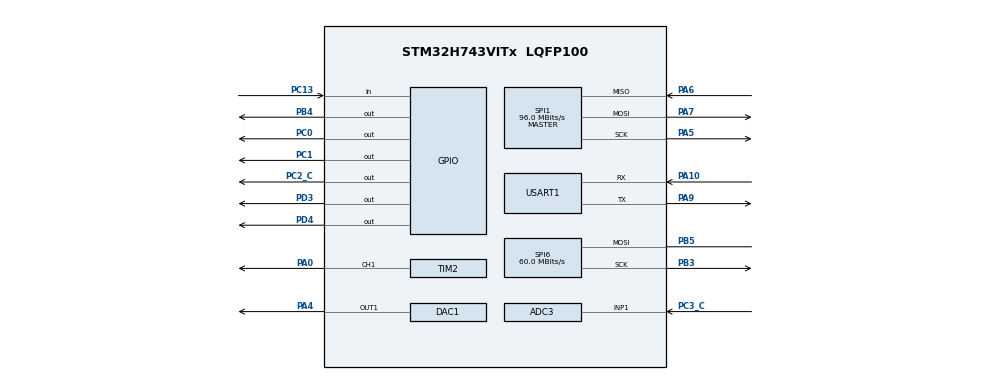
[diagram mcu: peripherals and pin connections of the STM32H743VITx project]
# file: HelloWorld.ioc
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ADC3.Channel-0\#ChannelRegularConversion=ADC_CHANNEL_1
ADC3.ClockPrescalerADC3=ADC_CLOCK_ASYNC_DIV2
ADC3.ContinuousConvMode=DISABLE
ADC3.ConversionDataManagement=ADC_CONVERSIONDATA_DMA_CIRCULAR
ADC3.DiscontinuousConvMode=DISABLE
ADC3.EnableAnalogWatchDog1=false
ADC3.ExternalTrigConv=ADC_EXTERNALTRIG_T1_CC1
ADC3.ExternalTrigConvEdge=ADC_EXTERNALTRIGCONVEDGE_RISING
ADC3.NbrOfConversion=1
ADC3.NbrOfConversionFlag=1
ADC3.OffsetNumber-0\#ChannelRegularConversion=ADC_OFFSET_NONE
ADC3.OffsetSignedSaturation-0\#ChannelRegularConversion=DISABLE
ADC3.Overrun=ADC_OVR_DATA_OVERWRITTEN
ADC3.Rank-0\#ChannelRegularConversion=1
ADC3.Resolution=ADC_RESOLUTION_12B
ADC3.SamplingTime-0\#ChannelRegularConversion=ADC_SAMPLETIME_1CYCLE_5
CORTEX_M7.AccessPermission_S-Cortex_Memory_Protection_Unit_Region1_Settings_S=MPU_REGION_FULL_ACCESS
CORTEX_M7.AccessPermission_S-Cortex_Memory_Protection_Unit_Region2_Settings_S=MPU_REGION_FULL_ACCESS
CORTEX_M7.AccessPermission_S-Cortex_Memory_Protection_Unit_Region3_Settings_S=MPU_REGION_FULL_ACCESS
CORTEX_M7.AccessPermission_S-Cortex_Memory_Protection_Unit_Region4_Settings_S=MPU_REGION_FULL_ACCESS
CORTEX_M7.AccessPermission_S-Cortex_Memory_Protection_Unit_Region5_Settings_S=MPU_REGION_FULL_ACCESS
CORTEX_M7.AccessPermission_Spec=MPU_REGION_FULL_ACCESS
CORTEX_M7.BaseAddress_S-Cortex_Memory_Protection_Unit_Region1_Settings_S=0x60000000
CORTEX_M7.BaseAddress_S-Cortex_Memory_Protection_Unit_Region2_Settings_S=0x30000000
CORTEX_M7.BaseAddress_S-Cortex_Memory_Protection_Unit_Region3_Settings_S=0x30020000
CORTEX_M7.BaseAddress_S-Cortex_Memory_Protection_Unit_Region4_Settings_S=0x30040000
CORTEX_M7.BaseAddress_S-Cortex_Memory_Protection_Unit_Region5_Settings_S=0x38000000
CORTEX_M7.BaseAddress_Spec=0x24000000
CORTEX_M7.CPU_DCache=Enabled
CORTEX_M7.CPU_ICache=Enabled
CORTEX_M7.DisableExec_Spec=MPU_INSTRUCTION_ACCESS_ENABLE
CORTEX_M7.Enable-Cortex_Memory_Protection_Unit_Region0_Settings=MPU_REGION_ENABLE
CORTEX_M7.Enable-Cortex_Memory_Protection_Unit_Region1_Settings=MPU_REGION_ENABLE
CORTEX_M7.Enable-Cortex_Memory_Protection_Unit_Region2_Settings=MPU_REGION_ENABLE
CORTEX_M7.Enable_S-Cortex_Memory_Protection_Unit_Region1_Settings_S=MPU_REGION_ENABLE
CORTEX_M7.Enable_S-Cortex_Memory_Protection_Unit_Region2_Settings_S=MPU_REGION_ENABLE
CORTEX_M7.Enable_S-Cortex_Memory_Protection_Unit_Region3_Settings_S=MPU_REGION_ENABLE
CORTEX_M7.Enable_S-Cortex_Memory_Protection_Unit_Region4_Settings_S=MPU_REGION_ENABLE
CORTEX_M7.Enable_S-Cortex_Memory_Protection_Unit_Region5_Settings_S=MPU_REGION_ENABLE
CORTEX_M7.IsBufferable_S-Cortex_Memory_Protection_Unit_Region1_Settings_S=MPU_ACCESS_BUFFERABLE
CORTEX_M7.IsBufferable_Spec=MPU_ACCESS_BUFFERABLE
CORTEX_M7.IsCacheable_S-Cortex_Memory_Protection_Unit_Region1_Settings_S=MPU_ACCESS_NOT_CACHEABLE
CORTEX_M7.IsCacheable_S-Cortex_Memory_Protection_Unit_Region2_Settings_S=MPU_ACCESS_CACHEABLE
CORTEX_M7.IsCacheable_S-Cortex_Memory_Protection_Unit_Region3_Settings_S=MPU_ACCESS_CACHEABLE
CORTEX_M7.IsCacheable_S-Cortex_Memory_Protection_Unit_Region4_Settings_S=MPU_ACCESS_CACHEABLE
CORTEX_M7.IsCacheable_S-Cortex_Memory_Protection_Unit_Region5_Settings_S=MPU_ACCESS_CACHEABLE
CORTEX_M7.IsCacheable_Spec=MPU_ACCESS_CACHEABLE
CORTEX_M7.IsShareable_S-Cortex_Memory_Protection_Unit_Region5_Settings_S=MPU_ACCESS_NOT_SHAREABLE
CORTEX_M7.IsShareable_Spec=MPU_ACCESS_NOT_SHAREABLE
CORTEX_M7.MPU_Control=MPU_HFNMI_PRIVDEF
CORTEX_M7.Size_S-Cortex_Memory_Protection_Unit_Region1_Settings_S=MPU_REGION_SIZE_64KB
CORTEX_M7.Size_S-Cortex_Memory_Protection_Unit_Region2_Settings_S=MPU_REGION_SIZE_128KB
CORTEX_M7.Size_S-Cortex_Memory_Protection_Unit_Region3_Settings_S=MPU_REGION_SIZE_128KB
CORTEX_M7.Size_S-Cortex_Memory_Protection_Unit_Region4_Settings_S=MPU_REGION_SIZE_32KB
CORTEX_M7.Size_S-Cortex_Memory_Protection_Unit_Region5_Settings_S=MPU_REGION_SIZE_64KB
CORTEX_M7.Size_Spec=MPU_REGION_SIZE_512KB
CORTEX_M7.SubRegionDisable_Spec=0x0
CORTEX_M7.TypeExtField_Spec=MPU_TEX_LEVEL1
CORTEX_M7.default_mode_Activation=1
DAC1.DAC1_OutputBuffer-DAC_OUT1=DAC_OUTPUTBUFFER_ENABLE
DAC1.DAC_Channel-DAC_OUT1=DAC_CHANNEL_1
DAC1.DAC_SampleAndHold-DAC_OUT1=DAC_SAMPLEANDHOLD_DISABLE
DAC1.DAC_Trigger-DAC_OUT1=DAC_TRIGGER_T6_TRGO
DAC1.DAC_UserTrimming-DAC_OUT1=DAC_TRIMMING_FACTORY
Dma.ADC3.2.Direction=DMA_PERIPH_TO_MEMORY
Dma.ADC3.2.EventEnable=DISABLE
Dma.ADC3.2.FIFOMode=DMA_FIFOMODE_ENABLE
Dma.ADC3.2.FIFOThreshold=DMA_FIFO_THRESHOLD_FULL
Dma.ADC3.2.Instance=DMA2_Stream0
Dma.ADC3.2.MemBurst=DMA_MBURST_SINGLE
Dma.ADC3.2.MemDataAlignment=DMA_MDATAALIGN_HALFWORD
Dma.ADC3.2.MemInc=DMA_MINC_ENABLE
Dma.ADC3.2.Mode=DMA_CIRCULAR
Dma.ADC3.2.PeriphBurst=DMA_PBURST_SINGLE
Dma.ADC3.2.PeriphDataAlignment=DMA_PDATAALIGN_HALFWORD
Dma.ADC3.2.PeriphInc=DMA_PINC_DISABLE
Dma.ADC3.2.Polarity=HAL_DMAMUX_REQ_GEN_RISING
Dma.ADC3.2.Priority=DMA_PRIORITY_HIGH
Dma.ADC3.2.RequestNumber=1
Dma.ADC3.2.SignalID=NONE
Dma.ADC3.2.SyncEnable=DISABLE
Dma.ADC3.2.SyncPolarity=HAL_DMAMUX_SYNC_NO_EVENT
Dma.ADC3.2.SyncRequestNumber=1
Dma.ADC3.2.SyncSignalID=NONE
Dma.DAC1_CH1.3.Direction=DMA_MEMORY_TO_PERIPH
Dma.DAC1_CH1.3.EventEnable=DISABLE
Dma.DAC1_CH1.3.FIFOMode=DMA_FIFOMODE_ENABLE
Dma.DAC1_CH1.3.FIFOThreshold=DMA_FIFO_THRESHOLD_FULL
Dma.DAC1_CH1.3.Instance=DMA2_Stream1
Dma.DAC1_CH1.3.MemBurst=DMA_MBURST_INC8
Dma.DAC1_CH1.3.MemDataAlignment=DMA_MDATAALIGN_HALFWORD
Dma.DAC1_CH1.3.MemInc=DMA_MINC_ENABLE
Dma.DAC1_CH1.3.Mode=DMA_CIRCULAR
Dma.DAC1_CH1.3.PeriphBurst=DMA_PBURST_SINGLE
Dma.DAC1_CH1.3.PeriphDataAlignment=DMA_PDATAALIGN_HALFWORD
Dma.DAC1_CH1.3.PeriphInc=DMA_PINC_DISABLE
Dma.DAC1_CH1.3.Polarity=HAL_DMAMUX_REQ_GEN_RISING
Dma.DAC1_CH1.3.Priority=DMA_PRIORITY_MEDIUM
Dma.DAC1_CH1.3.RequestNumber=1
Dma.DAC1_CH1.3.SignalID=NONE
Dma.DAC1_CH1.3.SyncEnable=DISABLE
Dma.DAC1_CH1.3.SyncPolarity=HAL_DMAMUX_SYNC_NO_EVENT
Dma.DAC1_CH1.3.SyncRequestNumber=1
Dma.DAC1_CH1.3.SyncSignalID=NONE
Dma.Request0=USART1_RX
Dma.Request1=USART1_TX
Dma.Request2=ADC3
Dma.Request3=DAC1_CH1
Dma.USART1_RX.0.Direction=DMA_PERIPH_TO_MEMORY
Dma.USART1_RX.0.EventEnable=DISABLE
Dma.USART1_RX.0.FIFOMode=DMA_FIFOMODE_DISABLE
Dma.USART1_RX.0.Instance=DMA1_Stream0
Dma.USART1_RX.0.MemDataAlignment=DMA_MDATAALIGN_BYTE
Dma.USART1_RX.0.MemInc=DMA_MINC_ENABLE
Dma.USART1_RX.0.Mode=DMA_CIRCULAR
Dma.USART1_RX.0.PeriphDataAlignment=DMA_PDATAALIGN_BYTE
Dma.USART1_RX.0.PeriphInc=DMA_PINC_DISABLE
Dma.USART1_RX.0.Polarity=HAL_DMAMUX_REQ_GEN_RISING
Dma.USART1_RX.0.Priority=DMA_PRIORITY_MEDIUM
Dma.USART1_RX.0.RequestNumber=1
Dma.USART1_RX.0.SignalID=NONE
Dma.USART1_RX.0.SyncEnable=DISABLE
Dma.USART1_RX.0.SyncPolarity=HAL_DMAMUX_SYNC_NO_EVENT
Dma.USART1_RX.0.SyncRequestNumber=1
Dma.USART1_RX.0.SyncSignalID=NONE
Dma.USART1_TX.1.Direction=DMA_MEMORY_TO_PERIPH
Dma.USART1_TX.1.EventEnable=DISABLE
Dma.USART1_TX.1.FIFOMode=DMA_FIFOMODE_ENABLE
Dma.USART1_TX.1.FIFOThreshold=DMA_FIFO_THRESHOLD_FULL
Dma.USART1_TX.1.Instance=DMA1_Stream1
Dma.USART1_TX.1.MemBurst=DMA_MBURST_INC16
Dma.USART1_TX.1.MemDataAlignment=DMA_MDATAALIGN_BYTE
Dma.USART1_TX.1.MemInc=DMA_MINC_ENABLE
Dma.USART1_TX.1.Mode=DMA_NORMAL
Dma.USART1_TX.1.PeriphBurst=DMA_PBURST_SINGLE
Dma.USART1_TX.1.PeriphDataAlignment=DMA_PDATAALIGN_BYTE
Dma.USART1_TX.1.PeriphInc=DMA_PINC_DISABLE
Dma.USART1_TX.1.Polarity=HAL_DMAMUX_REQ_GEN_RISING
Dma.USART1_TX.1.Priority=DMA_PRIORITY_MEDIUM
Dma.USART1_TX.1.RequestNumber=1
Dma.USART1_TX.1.SignalID=NONE
Dma.USART1_TX.1.SyncEnable=DISABLE
Dma.USART1_TX.1.SyncPolarity=HAL_DMAMUX_SYNC_NO_EVENT
Dma.USART1_TX.1.SyncRequestNumber=1
Dma.USART1_TX.1.SyncSignalID=NONE
Mcu.Family=STM32H7
Mcu.Name=STM32H743VITx
Mcu.Package=LQFP100
NVIC.DMA1_Stream0_IRQn=true\:0\:0\:false\:false\:true\:false\:true\:true
NVIC.DMA1_Stream1_IRQn=true\:0\:0\:false\:false\:true\:false\:true\:true
NVIC.DMA2_Stream0_IRQn=true\:0\:0\:false\:false\:true\:false\:true\:true
NVIC.DMA2_Stream1_IRQn=true\:0\:0\:false\:false\:true\:false\:true\:true
NVIC.PriorityGroup=NVIC_PRIORITYGROUP_4
NVIC.TIM7_IRQn=true\:0\:0\:false\:false\:true\:true\:true\:true
NVIC.USART1_IRQn=true\:0\:0\:false\:false\:true\:true\:true\:true
PA0.Signal=S_TIM2_CH1_ETR
PA10.Mode=Asynchronous
PA10.Signal=USART1_RX
PA13\ (JTMS/SWDIO).Mode=Serial_Wire
PA13\ (JTMS/SWDIO).Signal=DEBUG_JTMS-SWDIO
PA14\ (JTCK/SWCLK).Mode=Serial_Wire
PA14\ (JTCK/SWCLK).Signal=DEBUG_JTCK-SWCLK
PA4.Signal=COMP_DAC11_group
PA5.Mode=Full_Duplex_Master
PA5.Signal=SPI1_SCK
PA6.Mode=Full_Duplex_Master
PA6.Signal=SPI1_MISO
PA7.Mode=Full_Duplex_Master
PA7.Signal=SPI1_MOSI
PA9.Mode=Asynchronous
PA9.Signal=USART1_TX
PB3\ (JTDO/TRACESWO).GPIO_PuPd=GPIO_PULLUP
PB3\ (JTDO/TRACESWO).GPIO_Speed=GPIO_SPEED_FREQ_VERY_HIGH
PB3\ (JTDO/TRACESWO).Mode=Simplex_Bidirectional_Master
PB3\ (JTDO/TRACESWO).Signal=SPI6_SCK
PB4\ (NJTRST).Signal=GPIO_Output
PB5.GPIO_PuPd=GPIO_PULLUP
PB5.GPIO_Speed=GPIO_SPEED_FREQ_VERY_HIGH
PB5.Mode=Simplex_Bidirectional_Master
PB5.Signal=SPI6_MOSI
PC0.Signal=GPIO_Output
PC1.Signal=GPIO_Output
PC13.Signal=GPIO_Input
PC2_C.Signal=GPIO_Output
PC3_C.Mode=IN1-Single-Ended
PC3_C.Signal=ADC3_INP1
PD3.Signal=GPIO_Output
PD4.Signal=GPIO_Output
PH0-OSC_IN\ (PH0).Mode=HSE-External-Oscillator
PH0-OSC_IN\ (PH0).Signal=RCC_OSC_IN
PH1-OSC_OUT\ (PH1).Mode=HSE-External-Oscillator
PH1-OSC_OUT\ (PH1).Signal=RCC_OSC_OUT
ProjectManager.HeapSize=0x2000
ProjectManager.StackSize=0x1000
ProjectManager.TargetToolchain=STM32CubeIDE
RCC.ADCFreq_Value=75000000
RCC.APB1Freq_Value=120000000
RCC.APB2Freq_Value=120000000
RCC.APB3Freq_Value=120000000
RCC.APB4Freq_Value=120000000
RCC.CortexFreq_Value=480000000
RCC.D1PPRE=RCC_APB3_DIV2
RCC.D2PPRE1=RCC_APB1_DIV2
RCC.D2PPRE2=RCC_APB2_DIV2
RCC.D3PPRE=RCC_APB4_DIV2
RCC.DIVM1=5
RCC.DIVM2=2
RCC.DIVN1=192
RCC.DIVN2=12
RCC.DIVQ1=5
RCC.HCLKFreq_Value=240000000
RCC.HPRE=RCC_HCLK_DIV2
RCC.PLL2FRACN=0
RCC.PLL3FRACN=0
RCC.PLLFRACN=0
RCC.PLLSourceVirtual=RCC_PLLSOURCE_HSE
RCC.SYSCLKFreq_VALUE=480000000
RCC.SYSCLKSource=RCC_SYSCLKSOURCE_PLLCLK
RCC.USBFreq_Value=192000000
SH.COMP_DAC11_group.0=DAC1_OUT1,DAC_OUT1
SH.S_TIM2_CH1_ETR.0=TIM2_CH1,PWM Generation1 CH1
SPI1.BaudRatePrescaler=SPI_BAUDRATEPRESCALER_2
SPI1.CalculateBaudRate=96.0 MBits/s
SPI1.DataSize=SPI_DATASIZE_16BIT
SPI1.Direction=SPI_DIRECTION_2LINES
SPI1.Mode=SPI_MODE_MASTER
SPI1.VirtualType=VM_MASTER
SPI6.BaudRatePrescaler=SPI_BAUDRATEPRESCALER_2
SPI6.CLKPhase=SPI_PHASE_2EDGE
SPI6.CLKPolarity=SPI_POLARITY_HIGH
SPI6.CalculateBaudRate=60.0 MBits/s
SPI6.DataSize=SPI_DATASIZE_8BIT
SPI6.Direction=SPI_DIRECTION_1LINE
SPI6.Mode=SPI_MODE_MASTER
SPI6.VirtualType=VM_MASTER
TIM1.AutoReloadPreload=TIM_AUTORELOAD_PRELOAD_DISABLE
TIM1.Channel-PWM\ Generation1\ No\ Output=TIM_CHANNEL_1
TIM1.OC1Preload_PWM=DISABLE
TIM1.OCPolarity_1=TIM_OCPOLARITY_LOW
TIM1.TIM_MasterOutputTrigger=TIM_TRGO_RESET
TIM1.TIM_MasterOutputTrigger2=TIM_TRGO2_RESET
TIM1.TIM_MasterSlaveMode=TIM_MASTERSLAVEMODE_DISABLE
TIM2.Channel-PWM\ Generation1\ CH1=TIM_CHANNEL_1
TIM6.TIM_MasterOutputTrigger=TIM_TRGO_UPDATE
USART1.VirtualMode-Asynchronous=VM_ASYNC
VP_TIM1_VS_ClockSourceINT.Mode=Internal
VP_TIM1_VS_no_output1.Mode=PWM Generation1 No Output
VP_TIM2_VS_ClockSourceINT.Mode=Internal
VP_TIM6_VS_ClockSourceINT.Mode=Enable_Timer
VP_TIM7_VS_ClockSourceINT.Mode=Enable_Timer
board=custom

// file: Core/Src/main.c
/* USER CODE BEGIN Header */
/**
  ******************************************************************************
  * @file           : main.c
  * @brief          : Main program body
  ******************************************************************************
  * @attention
  *
  * Copyright (c) 2024 STMicroelectronics.
  * All rights reserved.
  *
  * This software is licensed under terms that can be found in the LICENSE file
  * in the root directory of this software component.
  * If no LICENSE file comes with this software, it is provided AS-IS.
  *
  ******************************************************************************
  */
/* USER CODE END Header */
#include "main.h"
#include "adc.h"
#include "dac.h"
#include "dma.h"
#include "spi.h"
#include "tim.h"
#include "usart.h"
#include "gpio.h"

/* USER CODE BEGIN Includes */
#include "common_inc.h"
/* USER CODE END Includes */

void SystemClock_Config(void);
void PeriphCommonClock_Config(void);
static void MPU_Config(void);

int main(void)
{

  /* USER CODE BEGIN 1 */
#if 0
    uint32_t *SouceAddr = (uint32_t *)FLASH_BANK1_BASE;
	uint32_t *DestAddr =  (uint32_t *)D1_DTCMRAM_BASE;

	memcpy(DestAddr, SouceAddr, 0x400);

	/* 设置中断向量表到ITCM里面 */
	SCB->VTOR = D1_DTCMRAM_BASE;
#endif
  /* USER CODE END 1 */

  /* MPU Configuration--------------------------------------------------------*/
  MPU_Config();

  /* Enable the CPU Cache */

  /* Enable I-Cache---------------------------------------------------------*/
  SCB_EnableICache();

  /* Enable D-Cache---------------------------------------------------------*/
  SCB_EnableDCache();

  /* MCU Configuration--------------------------------------------------------*/

  /* Reset of all peripherals, Initializes the Flash interface and the Systick. */
  LL_APB4_GRP1_EnableClock(LL_APB4_GRP1_PERIPH_SYSCFG);

  /* System interrupt init*/
  NVIC_SetPriorityGrouping(NVIC_PRIORITYGROUP_4);

  /* SysTick_IRQn interrupt configuration */
  NVIC_SetPriority(SysTick_IRQn, NVIC_EncodePriority(NVIC_GetPriorityGrouping(),15, 0));

  /* Configure the system clock */
  SystemClock_Config();

/* Configure the peripherals common clocks */
  PeriphCommonClock_Config();

  /* Initialize all configured peripherals */
  MX_GPIO_Init();
  MX_DMA_Init();
  MX_TIM7_Init();
  MX_ADC3_Init();
  MX_USART1_UART_Init();
  MX_TIM1_Init();
  MX_DAC1_Init();
  MX_TIM6_Init();
  MX_SPI6_Init();
  MX_TIM2_Init();
  MX_SPI1_Init();

  /* Infinite loop */
  /* USER CODE BEGIN WHILE */
   Main();
  while (1)
  {
    /* USER CODE END WHILE */

  }
}

void SystemClock_Config(void)
{
  LL_FLASH_SetLatency(LL_FLASH_LATENCY_4);
  while(LL_FLASH_GetLatency()!= LL_FLASH_LATENCY_4)
  {
  }
  LL_PWR_ConfigSupply(LL_PWR_LDO_SUPPLY);
  LL_PWR_SetRegulVoltageScaling(LL_PWR_REGU_VOLTAGE_SCALE0);
  while (LL_PWR_IsActiveFlag_VOS() == 0)
  {
  }
  LL_RCC_HSE_Enable();

   /* Wait till HSE is ready */
  while(LL_RCC_HSE_IsReady() != 1)
  {

  }
  LL_RCC_PLL_SetSource(LL_RCC_PLLSOURCE_HSE);
  LL_RCC_PLL1P_Enable();
  LL_RCC_PLL1Q_Enable();
  LL_RCC_PLL1R_Enable();
  LL_RCC_PLL1_SetVCOInputRange(LL_RCC_PLLINPUTRANGE_4_8);
  LL_RCC_PLL1_SetVCOOutputRange(LL_RCC_PLLVCORANGE_WIDE);
  LL_RCC_PLL1_SetM(5);
  LL_RCC_PLL1_SetN(192);
  LL_RCC_PLL1_SetP(2);
  LL_RCC_PLL1_SetQ(5);
  LL_RCC_PLL1_SetR(2);
  LL_RCC_PLL1_Enable();

   /* Wait till PLL is ready */
  while(LL_RCC_PLL1_IsReady() != 1)
  {
  }

   /* Intermediate AHB prescaler 2 when target frequency clock is higher than 80 MHz */
   LL_RCC_SetAHBPrescaler(LL_RCC_AHB_DIV_2);

  LL_RCC_SetSysClkSource(LL_RCC_SYS_CLKSOURCE_PLL1);

   /* Wait till System clock is ready */
  while(LL_RCC_GetSysClkSource() != LL_RCC_SYS_CLKSOURCE_STATUS_PLL1)
  {

  }
  LL_RCC_SetSysPrescaler(LL_RCC_SYSCLK_DIV_1);
  LL_RCC_SetAHBPrescaler(LL_RCC_AHB_DIV_2);
  LL_RCC_SetAPB1Prescaler(LL_RCC_APB1_DIV_2);
  LL_RCC_SetAPB2Prescaler(LL_RCC_APB2_DIV_2);
  LL_RCC_SetAPB3Prescaler(LL_RCC_APB3_DIV_2);
  LL_RCC_SetAPB4Prescaler(LL_RCC_APB4_DIV_2);

  LL_Init1msTick(480000000);

  LL_SetSystemCoreClock(480000000);
}

void PeriphCommonClock_Config(void)
{
  LL_RCC_PLL2P_Enable();
  LL_RCC_PLL2_SetVCOInputRange(LL_RCC_PLLINPUTRANGE_8_16);
  LL_RCC_PLL2_SetVCOOutputRange(LL_RCC_PLLVCORANGE_MEDIUM);
  LL_RCC_PLL2_SetM(2);
  LL_RCC_PLL2_SetN(12);
  LL_RCC_PLL2_SetP(2);
  LL_RCC_PLL2_SetQ(2);
  LL_RCC_PLL2_SetR(2);
  LL_RCC_PLL2_Enable();

   /* Wait till PLL is ready */
  while(LL_RCC_PLL2_IsReady() != 1)
  {
  }

}

 /* MPU Configuration */

void MPU_Config(void)
{

  /* Disables the MPU */
  LL_MPU_Disable();

  /** Initializes and configures the Region and the memory to be protected
  */
  LL_MPU_ConfigRegion(LL_MPU_REGION_NUMBER0, 0x0, 0x24000000, LL_MPU_REGION_SIZE_512KB|LL_MPU_TEX_LEVEL1|LL_MPU_REGION_FULL_ACCESS|LL_MPU_INSTRUCTION_ACCESS_ENABLE|LL_MPU_ACCESS_NOT_SHAREABLE|LL_MPU_ACCESS_CACHEABLE|LL_MPU_ACCESS_BUFFERABLE);

  /** Initializes and configures the Region and the memory to be protected
  */
  LL_MPU_ConfigRegion(LL_MPU_REGION_NUMBER1, 0x0, 0x60000000, LL_MPU_REGION_SIZE_64KB|LL_MPU_TEX_LEVEL0|LL_MPU_REGION_FULL_ACCESS|LL_MPU_INSTRUCTION_ACCESS_ENABLE|LL_MPU_ACCESS_NOT_SHAREABLE|LL_MPU_ACCESS_NOT_CACHEABLE|LL_MPU_ACCESS_BUFFERABLE);

  /** Initializes and configures the Region and the memory to be protected
  */
  LL_MPU_ConfigRegion(LL_MPU_REGION_NUMBER2, 0x0, 0x30000000, LL_MPU_REGION_SIZE_128KB|LL_MPU_TEX_LEVEL0|LL_MPU_REGION_FULL_ACCESS|LL_MPU_INSTRUCTION_ACCESS_ENABLE|LL_MPU_ACCESS_NOT_SHAREABLE|LL_MPU_ACCESS_CACHEABLE|LL_MPU_ACCESS_NOT_BUFFERABLE);

  /** Initializes and configures the Region and the memory to be protected
  */
  LL_MPU_ConfigRegion(LL_MPU_REGION_NUMBER3, 0x0, 0x30020000, LL_MPU_REGION_SIZE_128KB|LL_MPU_TEX_LEVEL0|LL_MPU_REGION_FULL_ACCESS|LL_MPU_INSTRUCTION_ACCESS_ENABLE|LL_MPU_ACCESS_NOT_SHAREABLE|LL_MPU_ACCESS_CACHEABLE|LL_MPU_ACCESS_NOT_BUFFERABLE);

  /** Initializes and configures the Region and the memory to be protected
  */
  LL_MPU_ConfigRegion(LL_MPU_REGION_NUMBER4, 0x0, 0x30040000, LL_MPU_REGION_SIZE_32KB|LL_MPU_TEX_LEVEL0|LL_MPU_REGION_FULL_ACCESS|LL_MPU_INSTRUCTION_ACCESS_ENABLE|LL_MPU_ACCESS_NOT_SHAREABLE|LL_MPU_ACCESS_CACHEABLE|LL_MPU_ACCESS_NOT_BUFFERABLE);

  /** Initializes and configures the Region and the memory to be protected
  */
  LL_MPU_ConfigRegion(LL_MPU_REGION_NUMBER5, 0x0, 0x38000000, LL_MPU_REGION_SIZE_64KB|LL_MPU_TEX_LEVEL0|LL_MPU_REGION_FULL_ACCESS|LL_MPU_INSTRUCTION_ACCESS_ENABLE|LL_MPU_ACCESS_NOT_SHAREABLE|LL_MPU_ACCESS_CACHEABLE|LL_MPU_ACCESS_NOT_BUFFERABLE);
  /* Enables the MPU */
  LL_MPU_Enable(LL_MPU_CTRL_HFNMI_PRIVDEF);

}

void Error_Handler(void)
{
  __disable_irq();
  while (1)
  {
  }
}
